# TM4C1294NCPDT register map
Vendor: Texas Instruments; File version: 2.2.0.295
CPU: CM4 r0p1, little endian, MPU, FPU, 3 interrupt priority bits
Registers are 32-bit, read-write, no defined reset value unless marked. A register's access mark holds for its fields unless they carry their own. Offsets are from the block's base; [hi:lo] are bit positions; {n}, {i} and the like mark numbered series; 'fields as' and 'values as' point back to an identical list.

## QEI0 — QEI (QEI0)
Base 0x4002C000
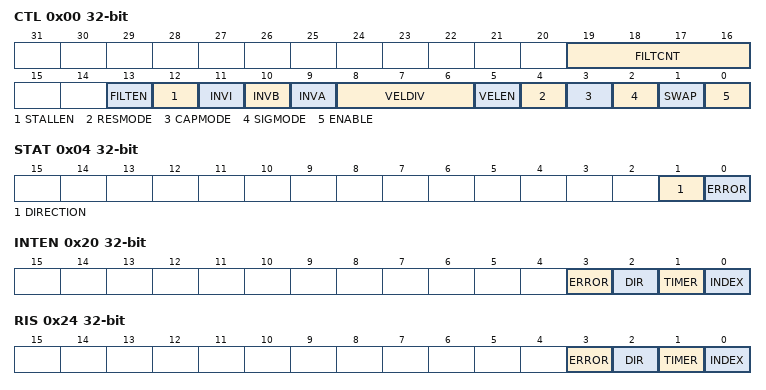
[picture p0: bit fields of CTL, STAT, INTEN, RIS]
0x00 CTL
  [19:16] FILTCNT — Input Filter Prescale Count
  [13] FILTEN — Enable Input Filter
  [12] STALLEN — Stall QEI
  [11] INVI — Invert Index Pulse
  [10] INVB — Invert PhB
  [9] INVA — Invert PhA
  [8:6] VELDIV — Predivide Velocity
    0=QEI clock /1; 1=QEI clock /2; 2=QEI clock /4; 3=QEI clock /8; 4=QEI clock /16; 5=QEI clock /32; 6=QEI clock /64; 7=QEI clock /128
  [5] VELEN — Capture Velocity
  [4] RESMODE — Reset Mode
  [3] CAPMODE — Capture Mode
  [2] SIGMODE — Signal Mode
  [1] SWAP — Swap Signals
  [0] ENABLE — Enable QEI
0x04 STAT
  [1] DIRECTION — Direction of Rotation
  [0] ERROR — Error Detected
0x08 POS
  [31:0] VALUE — Current Position Integrator
0x0C MAXPOS
  [31:0] VALUE — Maximum Position Integrator
0x10 LOAD
  [31:0] VALUE — Velocity Timer Load Value
0x14 TIME
  [31:0] VALUE — Velocity Timer Current Value
0x18 COUNT
  [31:0] VALUE — Velocity Pulse Count
0x1C SPEED
  [31:0] VALUE — Velocity
0x20 INTEN
  [3] ERROR — Phase Error Interrupt Enable
  [2] DIR — Direction Change Interrupt
  [1] TIMER — Timer Expires Interrupt Enable
  [0] INDEX — Index Pulse Detected Interrupt
0x24 RIS
  [3] ERROR — Phase Error Detected
  [2] DIR — Direction Change Detected
  [1] TIMER — Velocity Timer Expired
  [0] INDEX — Index Pulse Asserted
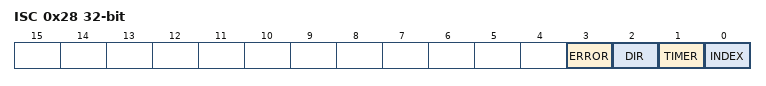
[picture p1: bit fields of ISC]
0x28 ISC
  [3] ERROR — Phase Error Interrupt
  [2] DIR — Direction Change Interrupt
  [1] TIMER — Velocity Timer Expired Interrupt
  [0] INDEX — Index Pulse Interrupt

## COMP — Comparator (COMP)
Base 0x4003C000
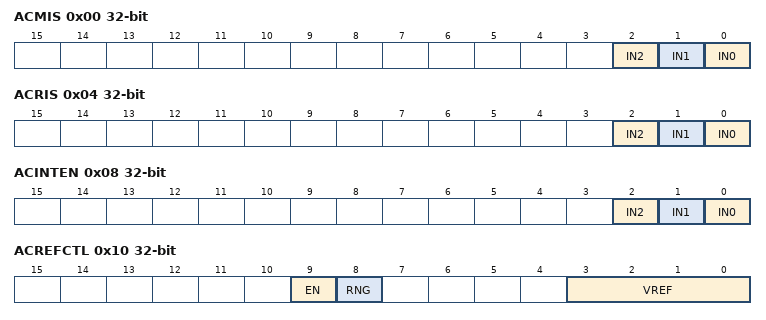
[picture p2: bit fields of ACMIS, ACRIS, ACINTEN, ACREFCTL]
0x00 ACMIS
  [2] IN2 — Comparator 2 Masked Interrupt
  [1] IN1 — Comparator 1 Masked Interrupt
  [0] IN0 — Comparator 0 Masked Interrupt
0x04 ACRIS
  [2] IN2 — Comparator 2 Interrupt Status
  [1] IN1 — Comparator 1 Interrupt Status
  [0] IN0 — Comparator 0 Interrupt Status
0x08 ACINTEN
  [2] IN2 — Comparator 2 Interrupt Enable
  [1] IN1 — Comparator 1 Interrupt Enable
  [0] IN0 — Comparator 0 Interrupt Enable
0x10 ACREFCTL
  [9] EN — Resistor Ladder Enable
  [8] RNG — Resistor Ladder Range
  [3:0] VREF — Resistor Ladder Voltage Ref
{0x20+0x20*i} ACSTAT{i} (i=0..2)
  [1] OVAL — Comparator Output Value
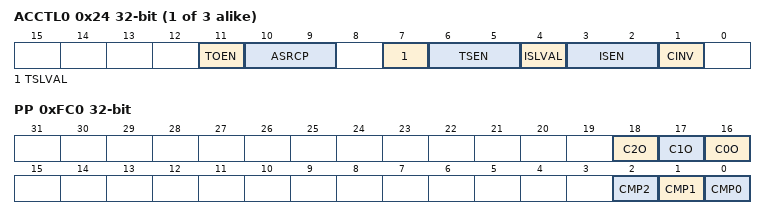
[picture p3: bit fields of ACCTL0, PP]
{0x24+0x20*i} ACCTL{i} (i=0..2)
  [11] TOEN — Trigger Output Enable
  [10:9] ASRCP — Analog Source Positive
    0=PIN (Pin value of Cn+); 1=PIN0 (Pin value of C0+); 2=REF (Internal voltage reference)
  [7] TSLVAL — Trigger Sense Level Value
  [6:5] TSEN — Trigger Sense
    0=LEVEL (Level sense, see TSLVAL); 1=FALL (Falling edge); 2=RISE (Rising edge); 3=BOTH (Either edge)
  [4] ISLVAL — Interrupt Sense Level Value
  [3:2] ISEN — Interrupt Sense
    0=LEVEL (Level sense, see ISLVAL); 1=FALL (Falling edge); 2=RISE (Rising edge); 3=BOTH (Either edge)
  [1] CINV — Comparator Output Invert
0xFC0 PP
  [18] C2O — Comparator Output 2 Present
  [17] C1O — Comparator Output 1 Present
  [16] C0O — Comparator Output 0 Present
  [2] CMP2 — Comparator 2 Present
  [1] CMP1 — Comparator 1 Present
  [0] CMP0 — Comparator 0 Present

## CAN0 — CAN (CAN0)
Base 0x40040000
Same registers: CAN1 0x40041000
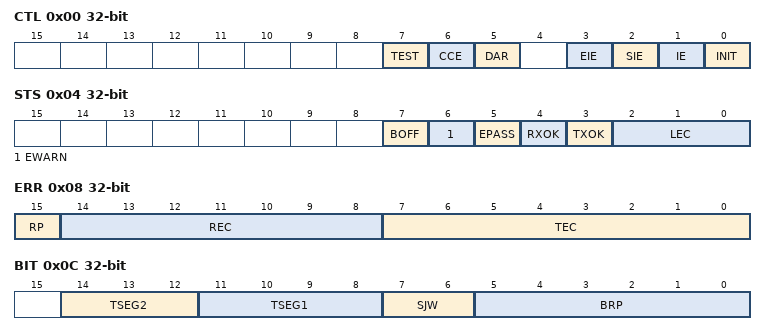
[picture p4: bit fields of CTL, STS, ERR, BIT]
0x00 CTL
  [7] TEST — Test Mode Enable
  [6] CCE — Configuration Change Enable
  [5] DAR — Disable Automatic-Retransmission
  [3] EIE — Error Interrupt Enable
  [2] SIE — Status Interrupt Enable
  [1] IE — CAN Interrupt Enable
  [0] INIT — Initialization
0x04 STS
  [7] BOFF — Bus-Off Status
  [6] EWARN — Warning Status
  [5] EPASS — Error Passive
  [4] RXOK — Received a Message Successfully
  [3] TXOK — Transmitted a Message
  [2:0] LEC — Last Error Code
    0=NONE (No Error); 1=STUFF (Stuff Error); 2=FORM (Format Error); 3=ACK (ACK Error); 4=BIT1 (Bit 1 Error); 5=BIT0 (Bit 0 Error); 6=CRC (CRC Error); 7=NOEVENT
0x08 ERR
  [15] RP — Received Error Passive
  [14:8] REC — Receive Error Counter
  [7:0] TEC — Transmit Error Counter
0x0C BIT
  [14:12] TSEG2 — Time Segment after Sample Point
  [11:8] TSEG1 — Time Segment Before Sample Point
  [7:6] SJW — (Re)Synchronization Jump Width
  [5:0] BRP — Baud Rate Prescaler
0x10 INT
  [15:0] INTID — Interrupt Identifier
    0=NONE (No interrupt pending); 0x8000=STATUS (Status Interrupt)
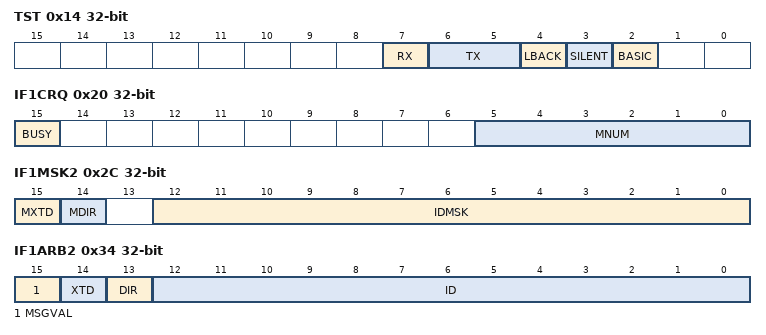
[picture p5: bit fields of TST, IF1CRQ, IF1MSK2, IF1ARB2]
0x14 TST
  [7] RX — Receive Observation
  [6:5] TX — Transmit Control
    0=CANCTL (CAN Module Control); 1=SAMPLE (Sample Point); 2=DOMINANT (Driven Low); 3=RECESSIVE (Driven High)
  [4] LBACK — Loopback Mode
  [3] SILENT — Silent Mode
  [2] BASIC — Basic Mode
0x18 BRPE
  [3:0] BRPE — Baud Rate Prescaler Extension
0x20 IF1CRQ
  [15] BUSY — Busy Flag
  [5:0] MNUM — Message Number
0x24 IF1CMSK
  [7] WRNRD — Write, Not Read
  [6] MASK — Access Mask Bits
  [5] ARB — Access Arbitration Bits
  [4] CONTROL — Access Control Bits
  [3] CLRINTPND — Clear Interrupt Pending Bit
  [2] NEWDAT — Access New Data
  [2] TXRQST — Access Transmission Request
  [1] DATAA — Access Data Byte 0 to 3
  [0] DATAB — Access Data Byte 4 to 7
0x28 IF1MSK1
  [15:0] IDMSK — Identifier Mask
0x2C IF1MSK2
  [15] MXTD — Mask Extended Identifier
  [14] MDIR — Mask Message Direction
  [12:0] IDMSK — Identifier Mask
0x30 IF1ARB1
  [15:0] ID — Message Identifier
0x34 IF1ARB2
  [15] MSGVAL — Message Valid
  [14] XTD — Extended Identifier
  [13] DIR — Message Direction
  [12:0] ID — Message Identifier
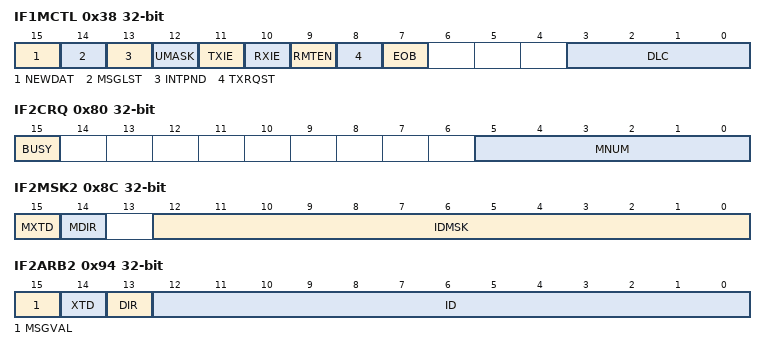
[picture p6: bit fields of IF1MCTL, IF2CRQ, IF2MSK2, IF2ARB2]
0x38 IF1MCTL
  [15] NEWDAT — New Data
  [14] MSGLST — Message Lost
  [13] INTPND — Interrupt Pending
  [12] UMASK — Use Acceptance Mask
  [11] TXIE — Transmit Interrupt Enable
  [10] RXIE — Receive Interrupt Enable
  [9] RMTEN — Remote Enable
  [8] TXRQST — Transmit Request
  [7] EOB — End of Buffer
  [3:0] DLC — Data Length Code
0x3C IF1DA1 read-modifies
  [15:0] DATA
0x40 IF1DA2 read-modifies
  [15:0] DATA
0x44 IF1DB1 read-modifies
  [15:0] DATA
0x48 IF1DB2 read-modifies
  [15:0] DATA
0x80 IF2CRQ
  [15] BUSY — Busy Flag
  [5:0] MNUM — Message Number
0x84 IF2CMSK
  fields as IF1CMSK
0x88 IF2MSK1
  [15:0] IDMSK — Identifier Mask
0x8C IF2MSK2
  fields as IF1MSK2
0x90 IF2ARB1
  [15:0] ID — Message Identifier
0x94 IF2ARB2
  fields as IF1ARB2
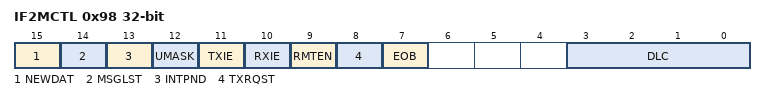
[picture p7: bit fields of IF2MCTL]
0x98 IF2MCTL
  fields as IF1MCTL
0x9C IF2DA1 read-modifies
  [15:0] DATA
0xA0 IF2DA2 read-modifies
  [15:0] DATA
0xA4 IF2DB1 read-modifies
  [15:0] DATA
0xA8 IF2DB2 read-modifies
  [15:0] DATA
0x100 TXRQ1
  [15:0] TXRQST — Transmission Request Bits
0x104 TXRQ2
  [15:0] TXRQST — Transmission Request Bits
0x120 NWDA1
  [15:0] NEWDAT — New Data Bits
0x124 NWDA2
  [15:0] NEWDAT — New Data Bits
0x140 MSG1INT
  [15:0] INTPND — Interrupt Pending Bits
0x144 MSG2INT
  [15:0] INTPND — Interrupt Pending Bits
0x160 MSG1VAL
  [15:0] MSGVAL — Message Valid Bits
0x164 MSG2VAL
  [15:0] MSGVAL — Message Valid Bits
